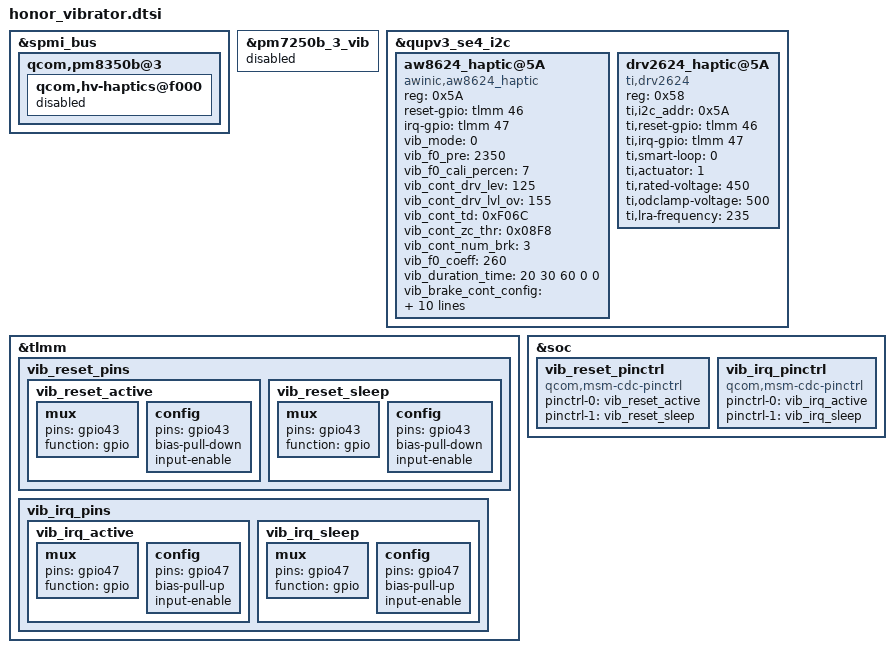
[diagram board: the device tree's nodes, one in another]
&spmi_bus {
	qcom,pm8350b@3 {
		qcom,hv-haptics@f000 {
			status="disabled";
		};
	};
};

&pm7250b_3_vib {
	status="disabled";
};

&qupv3_se4_i2c {
    status = "ok";
    aw8624_haptic@5A {
       compatible = "awinic,aw8624_haptic";
       reg = <0x5A>;
       reset-gpio = <&tlmm 46 0>;
       irq-gpio = <&tlmm 47 0>;
       vib_mode = < 0 >;  /*mode:  RAM mode->0; CONT mode -> 1*/
       vib_f0_pre = < 2350 >;
       vib_f0_cali_percen = < 7 >;
       vib_cont_drv_lev = < 125 >;
       vib_cont_drv_lvl_ov = < 155 >;
       vib_cont_td = < 0xF06C >;
       vib_cont_zc_thr = < 0x08F8 >;
       vib_cont_num_brk = < 3 >;
       vib_f0_coeff = < 260 >; /*Don't modify it*/
       vib_duration_time = < 20 30 60 0 0 >;
       vib_brake_cont_config = < 1 1 90 42 20 5 2 2 0 0 0  0  0  0 0 0 0 0 0   0  0  0 0 0 >;
       vib_f0_trace_parameter = < 9 5 1 15 >;
       vib_bemf_config = < 0x10 0x08 0x23 0xf8 >;
       vib_sw_brake = < 0x2c 0x08>; /*cont brake,other brake*/
       vib_wavseq = < 1 2 3 4 5 6 7 8 9 10 0 0 0 0 0 0 >; /*wavseq1-seq8 0x07-0x0E*/
       vib_wavloop = < 1 1 1 1 1 1 1 1 1 1>;/*loop1-mainloog 0x0f-0x13*/
       vib_td_brake = < 42720 42720 42720 >; /*level0  level1  level2*/
       vib_tset = < 0x11 >;
       vib_func_parameter1 = < 1 >;
       vib_calib_f0 = < 0 >;
       status = "okay";
       };
    drv2624_haptic@5A{
       compatible = "ti,drv2624";
       reg = <0x58>;
       ti,i2c_addr = <0x5A>;
       ti,reset-gpio = <&tlmm 46 0>;
       ti,irq-gpio = <&tlmm 47 0>;
       ti,smart-loop = <0>; /* 0-closeloop, 1-openloop */
       ti,actuator = <1>; /* 0-ERM, 1-LRA */
       ti,rated-voltage = <450>;
       ti,odclamp-voltage = <500>;
       ti,lra-frequency = <235>; /* DON'T Care if ERM */
       status = "okay";
       };

};
&tlmm {
    vib_reset_pins {
                        vib_reset_active: vib_reset_active {
                                mux {
                                        pins = "gpio43";
                                        function = "gpio";
                                };

                                config {
                                        pins = "gpio43";
                                        bias-pull-down;
                                        input-enable;
                                };
                        };

                        vib_reset_sleep: vib_reset_sleep {
                                mux {
                                        pins = "gpio43";
                                        function = "gpio";
                                };

                                config {
                                        pins = "gpio43";
                                        bias-pull-down;
                                        input-enable;
                                };
                        };
                };
    vib_irq_pins {
                        vib_irq_active: vib_irq_active {
                                mux {
                                        pins = "gpio47";
                                        function = "gpio";
                                };

                                config {
                                        pins = "gpio47";
                                        bias-pull-up;
                                        input-enable;
                                };
                        };

                        vib_irq_sleep: vib_irq_sleep {
                                mux {
                                        pins = "gpio47";
                                        function = "gpio";
                                };

                                config {
                                        pins = "gpio47";
                                        bias-pull-up;
                                        input-enable;
                                };
                        };
                };
};
&soc {
     vib_reset_pinctrl {
                compatible = "qcom,msm-cdc-pinctrl";
                pinctrl-names = "aud_active", "aud_sleep";
                pinctrl-0 = <&vib_reset_active>;
                pinctrl-1 = <&vib_reset_sleep>;
     };

     vib_irq_pinctrl {
                compatible = "qcom,msm-cdc-pinctrl";
                pinctrl-names = "aud_active", "aud_sleep";
                pinctrl-0 = <&vib_irq_active>;
                pinctrl-1 = <&vib_irq_sleep>;
     };

};
